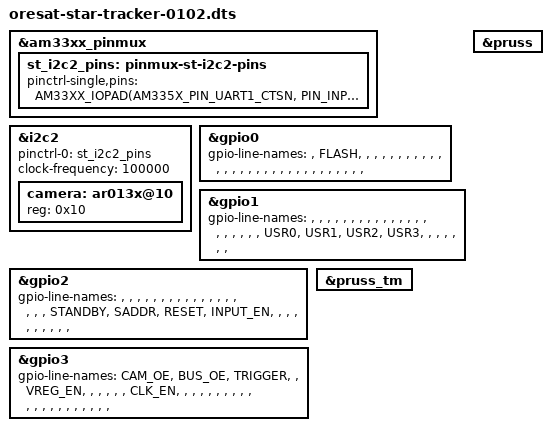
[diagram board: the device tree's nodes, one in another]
/* OreSat Star Tracker v1.2 device tree */

/dts-v1/;

#include "oresat-base.dtsi"

&am33xx_pinmux {
  st_i2c2_pins: pinmux-st-i2c2-pins {
    pinctrl-single,pins = <
      AM33XX_IOPAD(AM335X_PIN_UART1_CTSN, PIN_INPUT | MUX_MODE3) /* i2c2_sda */
      AM33XX_IOPAD(AM335X_PIN_UART1_RTSN, PIN_INPUT | MUX_MODE3) /* i2c2_scl */
    >;
  };
};

&i2c2 {
  #address-cells = <1>;
  #size-cells = <0>;
  status = "okay";
  pinctrl-names = "default";
  pinctrl-0 = <&st_i2c2_pins>;
  clock-frequency = <100000>;

  camera: ar013x@10 {
    reg = <0x10>;
  };
};

&gpio0 {
  gpio-line-names =
    /* 0  */ "",
    /* 1  */ "FLASH",
    /* 2  */ "",
    /* 3  */ "",
    /* 4  */ "",
    /* 5  */ "",
    /* 6  */ "",
    /* 7  */ "",
    /* 8  */ "",
    /* 9  */ "",
    /* 10 */ "",
    /* 11 */ "",
    /* 12 */ "",
    /* 13 */ "",
    /* 14 */ "",
    /* 15 */ "",
    /* 16 */ "",
    /* 17 */ "",
    /* 18 */ "",
    /* 19 */ "",
    /* 20 */ "",
    /* 21 */ "",
    /* 22 */ "",
    /* 23 */ "",
    /* 24 */ "",
    /* 25 */ "",
    /* 26 */ "",
    /* 27 */ "",
    /* 28 */ "",
    /* 29 */ "",
    /* 30 */ "",
    /* 31 */ "";
};

&gpio1 {
  gpio-line-names =
    /* 0  */ "",
    /* 1  */ "",
    /* 2  */ "",
    /* 3  */ "",
    /* 4  */ "",
    /* 5  */ "",
    /* 6  */ "",
    /* 7  */ "",
    /* 8  */ "",
    /* 9  */ "",
    /* 10 */ "",
    /* 11 */ "",
    /* 12 */ "",
    /* 13 */ "",
    /* 14 */ "",
    /* 15 */ "",
    /* 16 */ "",
    /* 17 */ "",
    /* 18 */ "",
    /* 19 */ "",
    /* 20 */ "",
    /* 21 */ "USR0",
    /* 22 */ "USR1",
    /* 23 */ "USR2",
    /* 24 */ "USR3",
    /* 25 */ "",
    /* 26 */ "",
    /* 27 */ "",
    /* 28 */ "",
    /* 29 */ "",
    /* 30 */ "",
    /* 31 */ "";
};

&gpio2 {
  gpio-line-names =
    /* 0  */ "",
    /* 1  */ "",
    /* 2  */ "",
    /* 3  */ "",
    /* 4  */ "",
    /* 5  */ "",
    /* 6  */ "",
    /* 7  */ "",
    /* 8  */ "",
    /* 9  */ "",
    /* 10 */ "",
    /* 11 */ "",
    /* 12 */ "",
    /* 13 */ "",
    /* 14 */ "",
    /* 15 */ "",
    /* 16 */ "",
    /* 17 */ "",
    /* 18 */ "STANDBY",
    /* 19 */ "SADDR",
    /* 20 */ "RESET",
    /* 21 */ "INPUT_EN",
    /* 22 */ "",
    /* 23 */ "",
    /* 24 */ "",
    /* 25 */ "",
    /* 26 */ "",
    /* 27 */ "",
    /* 28 */ "",
    /* 29 */ "",
    /* 30 */ "",
    /* 31 */ "";
};

&gpio3 {
  gpio-line-names =
    /* 0  */ "CAM_OE",
    /* 1  */ "BUS_OE",
    /* 2  */ "TRIGGER",
    /* 3  */ "",
    /* 4  */ "VREG_EN",
    /* 5  */ "",
    /* 6  */ "",
    /* 7  */ "",
    /* 8  */ "",
    /* 9  */ "",
    /* 10 */ "CLK_EN",
    /* 11 */ "",
    /* 12 */ "",
    /* 13 */ "",
    /* 14 */ "",
    /* 15 */ "",
    /* 16 */ "",
    /* 17 */ "",
    /* 18 */ "",
    /* 19 */ "",
    /* 20 */ "",
    /* 21 */ "",
    /* 22 */ "",
    /* 23 */ "",
    /* 24 */ "",
    /* 25 */ "",
    /* 26 */ "",
    /* 27 */ "",
    /* 28 */ "",
    /* 29 */ "",
    /* 30 */ "",
    /* 31 */ "";
};

&pruss {
  status = "okay";
};

&pruss_tm {
  status = "okay";
};
